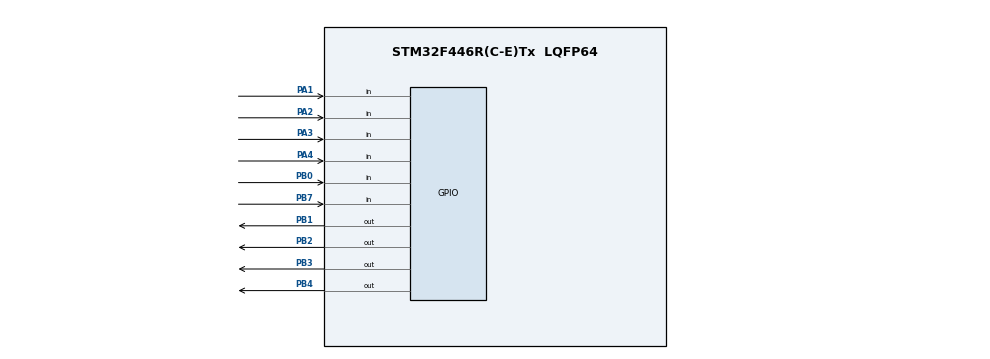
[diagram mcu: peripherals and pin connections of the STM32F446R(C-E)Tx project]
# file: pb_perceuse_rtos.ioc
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FREERTOS.Tasks01=defaultTask,0,128,StartDefaultTask,Default,NULL,Dynamic,NULL,NULL
Mcu.Family=STM32F4
Mcu.Name=STM32F446R(C-E)Tx
Mcu.Package=LQFP64
NVIC.PriorityGroup=NVIC_PRIORITYGROUP_4
PA1.Signal=GPIO_Input
PA2.Signal=GPIO_Input
PA3.Signal=GPIO_Input
PA4.Signal=GPIO_Input
PB0.Signal=GPIO_Input
PB1.Signal=GPIO_Output
PB2.Signal=GPIO_Output
PB3.Signal=GPIO_Output
PB4.Signal=GPIO_Output
PB7.Signal=GPIO_Input
ProjectManager.HeapSize=0x200
ProjectManager.StackSize=0x400
ProjectManager.TargetToolchain=STM32CubeIDE
RCC.CortexFreq_Value=16000000
RCC.USBFreq_Value=96000000
RCC.VCOOutputFreq_Value=192000000
VP_FREERTOS_VS_CMSIS_V1.Mode=CMSIS_V1
board=custom

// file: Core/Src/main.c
/* USER CODE BEGIN Header */
/**
  ******************************************************************************
  * @file           : main.c
  * @brief          : Main program body
  ******************************************************************************
  * @attention
  *
  * Copyright (c) 2024 STMicroelectronics.
  * All rights reserved.
  *
  * This software is licensed under terms that can be found in the LICENSE file
  * in the root directory of this software component.
  * If no LICENSE file comes with this software, it is provided AS-IS.
  *
  ******************************************************************************
  */
/* USER CODE END Header */
#include "main.h"
#include "cmsis_os.h"

osThreadId defaultTaskHandle;
/* USER CODE BEGIN PV */
TaskHandle_t AR,DE,MO,CNT;
/* USER CODE END PV */

void SystemClock_Config(void);
static void MX_GPIO_Init(void);

/* USER CODE BEGIN PFP */
void vArret_Urgence_Task(void *pvParameters);
void vMontee_Task(void *pvParameters);
void vDescente_Task(void *pvParameters);
void vControle_Task(void *pvParameters);
/* USER CODE END PFP */

int main(void)
{

  /* MCU Configuration--------------------------------------------------------*/

  /* Reset of all peripherals, Initializes the Flash interface and the Systick. */
  HAL_Init();

  /* Configure the system clock */
  SystemClock_Config();

  /* Initialize all configured peripherals */
  MX_GPIO_Init();

  /* Create the thread(s) */
  /* definition and creation of defaultTask */
  xTaskCreate(vDescente_Task,"desc",128,NULL,2,&DE);
  xTaskCreate(vMontee_Task,"monte",128,NULL,2,&MO);
  xTaskCreate(vArret_Urgence_Task,"urgence",128,NULL,1,&AR);
  xTaskCreate(vControle_Task,"cntr",128,NULL,2,&CNT);

  /* Start scheduler */
  osKernelStart();

  /* We should never get here as control is now taken by the scheduler */
  /* Infinite loop */
  while (1)
  {

  }
}

void SystemClock_Config(void)
{
  RCC_OscInitTypeDef RCC_OscInitStruct = {0};
  RCC_ClkInitTypeDef RCC_ClkInitStruct = {0};

  /** Configure the main internal regulator output voltage
  */
  __HAL_RCC_PWR_CLK_ENABLE();
  __HAL_PWR_VOLTAGESCALING_CONFIG(PWR_REGULATOR_VOLTAGE_SCALE3);

  /** Initializes the RCC Oscillators according to the specified parameters
  * in the RCC_OscInitTypeDef structure.
  */
  RCC_OscInitStruct.OscillatorType = RCC_OSCILLATORTYPE_HSI;
  RCC_OscInitStruct.HSIState = RCC_HSI_ON;
  RCC_OscInitStruct.HSICalibrationValue = RCC_HSICALIBRATION_DEFAULT;
  RCC_OscInitStruct.PLL.PLLState = RCC_PLL_NONE;
  if (HAL_RCC_OscConfig(&RCC_OscInitStruct) != HAL_OK)
  {
    Error_Handler();
  }

  /** Initializes the CPU, AHB and APB buses clocks
  */
  RCC_ClkInitStruct.ClockType = RCC_CLOCKTYPE_HCLK|RCC_CLOCKTYPE_SYSCLK
                              |RCC_CLOCKTYPE_PCLK1|RCC_CLOCKTYPE_PCLK2;
  RCC_ClkInitStruct.SYSCLKSource = RCC_SYSCLKSOURCE_HSI;
  RCC_ClkInitStruct.AHBCLKDivider = RCC_SYSCLK_DIV1;
  RCC_ClkInitStruct.APB1CLKDivider = RCC_HCLK_DIV1;
  RCC_ClkInitStruct.APB2CLKDivider = RCC_HCLK_DIV1;

  if (HAL_RCC_ClockConfig(&RCC_ClkInitStruct, FLASH_LATENCY_0) != HAL_OK)
  {
    Error_Handler();
  }
}

static void MX_GPIO_Init(void)
{
  GPIO_InitTypeDef GPIO_InitStruct = {0};

  /* GPIO Ports Clock Enable */
  __HAL_RCC_GPIOA_CLK_ENABLE();
  __HAL_RCC_GPIOB_CLK_ENABLE();

  /*Configure GPIO pin Output Level */
  HAL_GPIO_WritePin(GPIOB, GPIO_PIN_1|GPIO_PIN_2|GPIO_PIN_3|GPIO_PIN_4, GPIO_PIN_RESET);

  /*Configure GPIO pins : PA1 PA2 PA3 PA4 */
  GPIO_InitStruct.Pin = GPIO_PIN_1|GPIO_PIN_2|GPIO_PIN_3|GPIO_PIN_4;
  GPIO_InitStruct.Mode = GPIO_MODE_INPUT;
  GPIO_InitStruct.Pull = GPIO_NOPULL;
  HAL_GPIO_Init(GPIOA, &GPIO_InitStruct);

  /*Configure GPIO pins : PB0 PB7 */
  GPIO_InitStruct.Pin = GPIO_PIN_0|GPIO_PIN_7;
  GPIO_InitStruct.Mode = GPIO_MODE_INPUT;
  GPIO_InitStruct.Pull = GPIO_NOPULL;
  HAL_GPIO_Init(GPIOB, &GPIO_InitStruct);

  /*Configure GPIO pins : PB1 PB2 PB3 PB4 */
  GPIO_InitStruct.Pin = GPIO_PIN_1|GPIO_PIN_2|GPIO_PIN_3|GPIO_PIN_4;
  GPIO_InitStruct.Mode = GPIO_MODE_OUTPUT_PP;
  GPIO_InitStruct.Pull = GPIO_NOPULL;
  GPIO_InitStruct.Speed = GPIO_SPEED_FREQ_LOW;
  HAL_GPIO_Init(GPIOB, &GPIO_InitStruct);

}

void vMontee_Task(void *pvParameters)
{
  for(;;)
  {
	  while(HAL_GPIO_ReadPin(GPIOA,GPIO_PIN_3)!=GPIO_PIN_SET)
	  	{
	  	HAL_GPIO_WritePin(GPIOB,GPIO_PIN_3|1,GPIO_PIN_SET);
	  	}
	  HAL_GPIO_WritePin(GPIOB,GPIO_PIN_3|1,GPIO_PIN_RESET);
	  vTaskSuspend(MO);
  }
}
void vDescente_Task(void *pvParameters)
{
  for(;;)
  {
	  while(HAL_GPIO_ReadPin(GPIOA,GPIO_PIN_4)!=GPIO_PIN_SET)
	  	{
	  	HAL_GPIO_WritePin(GPIOB,GPIO_PIN_2|1,GPIO_PIN_SET);
	  	}
	  HAL_GPIO_WritePin(GPIOB,GPIO_PIN_2|1,GPIO_PIN_RESET);
	  vTaskSuspend(DE);
  }
}
void vArret_Urgence_Task(void *pvParameters)
{
  for(;;)
  {
    HAL_GPIO_WritePin(GPIOB,GPIO_PIN_1,GPIO_PIN_RESET);
	HAL_GPIO_WritePin(GPIOB,GPIO_PIN_3|4,GPIO_PIN_SET);
	while(HAL_GPIO_ReadPin(GPIOA,GPIO_PIN_3)!=GPIO_PIN_SET){}
	HAL_GPIO_WritePin(GPIOB,GPIO_PIN_3,GPIO_PIN_RESET);
	while(HAL_GPIO_ReadPin(GPIOA,GPIO_PIN_7)!=GPIO_PIN_SET){}
	vTaskSuspend(AR);
  }
}
void vControle_Task(void *pvParameters)
{
  for(;;)
  {
	  while(HAL_GPIO_ReadPin(GPIOA,GPIO_PIN_3)==GPIO_PIN_SET)
	     {
	     	vTaskResume(DE);
	     }
	     while(HAL_GPIO_ReadPin(GPIOA,GPIO_PIN_2)==GPIO_PIN_SET)
	         {
	    	 vTaskResume(MO);
	         }
	     while(HAL_GPIO_ReadPin(GPIOB,GPIO_PIN_0)==GPIO_PIN_SET)
	    	         {
	    	    	 vTaskResume(AR);
	    	         }
  }
  }
void Error_Handler(void)
{
  __disable_irq();
  while (1)
  {
  }
}
